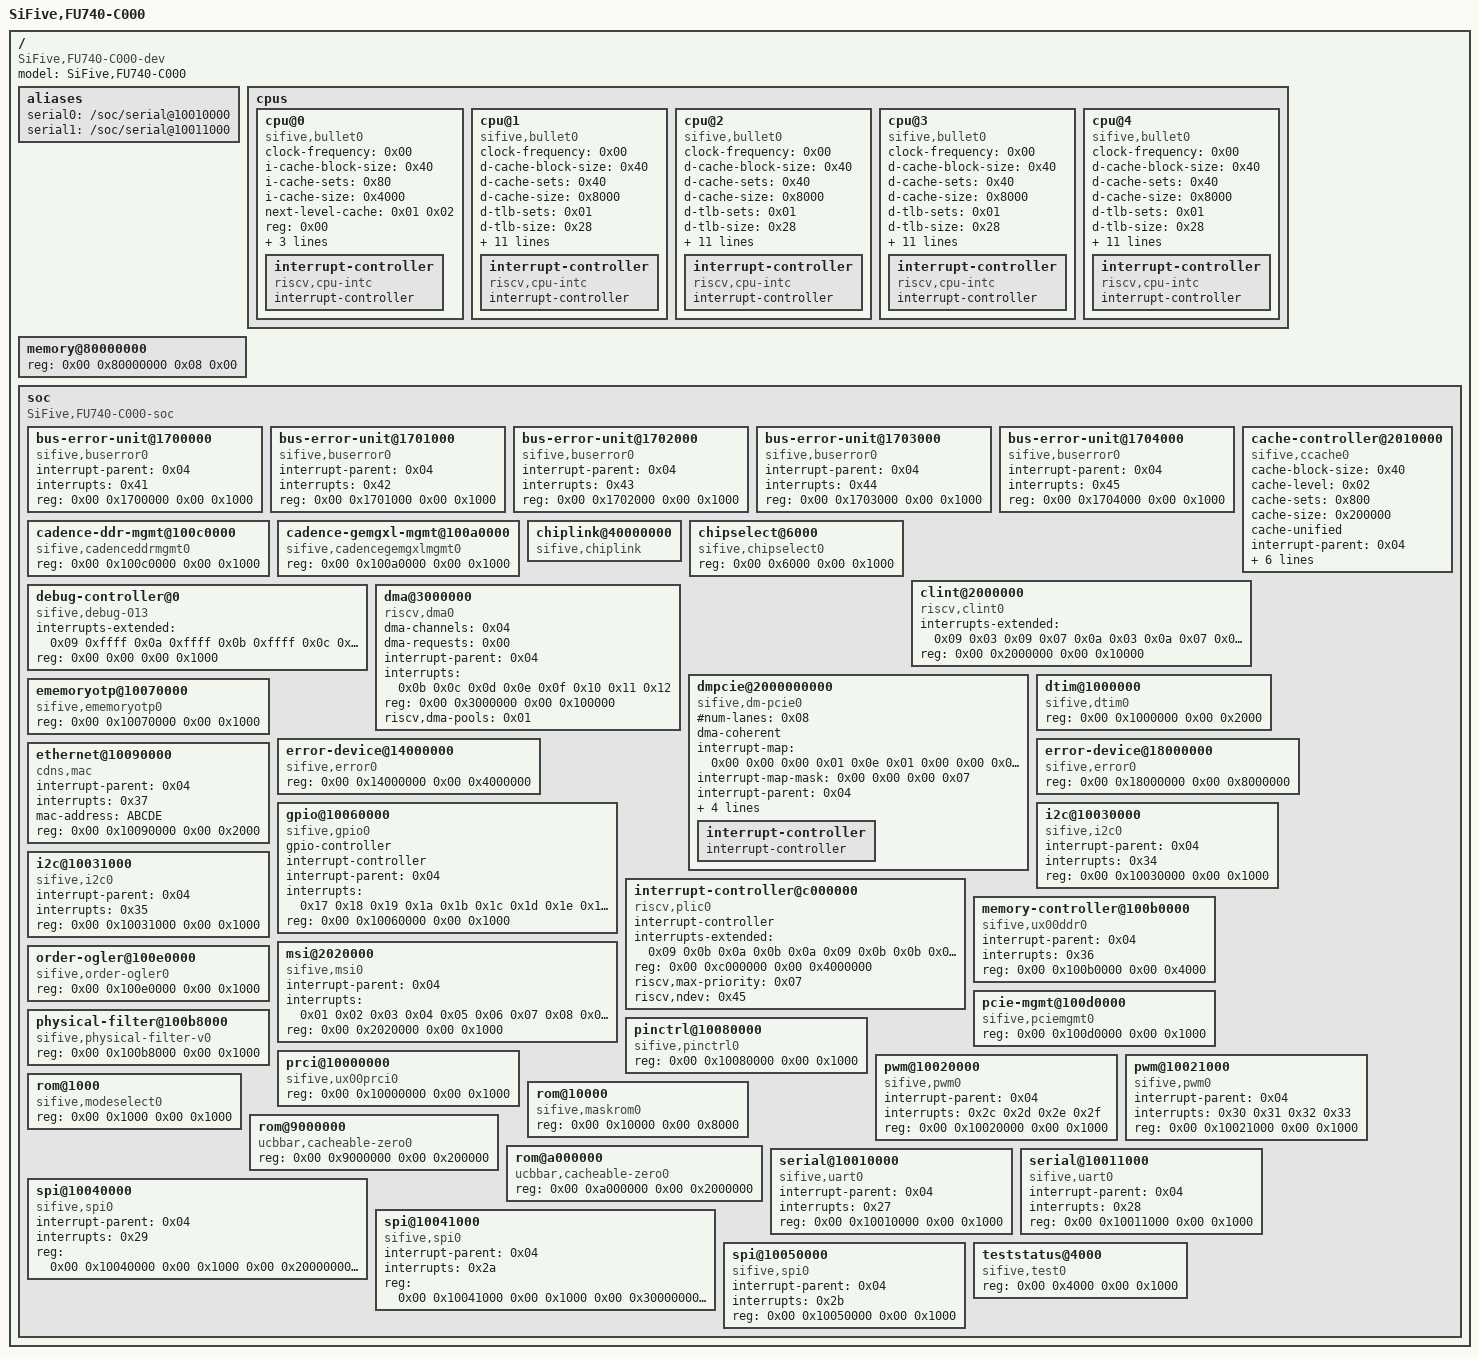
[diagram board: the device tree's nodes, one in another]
/dts-v1/;

/ {
	#address-cells = <0x02>;
	#size-cells = <0x02>;
	compatible = "SiFive,FU740-C000-dev\0fu700-dev\0sifive-dev";
	model = "SiFive,FU740-C000";

	aliases {
		serial0 = "/soc/serial@10010000";
		serial1 = "/soc/serial@10011000";
	};

	cpus {
		#address-cells = <0x01>;
		#size-cells = <0x00>;

		cpu@0 {
			clock-frequency = <0x00>;
			compatible = "sifive,bullet0\0riscv";
			device_type = "cpu";
			i-cache-block-size = <0x40>;
			i-cache-sets = <0x80>;
			i-cache-size = <0x4000>;
			next-level-cache = <0x01 0x02>;
			reg = <0x00>;
			riscv,isa = "rv64imac";
			sifive,dtim = <0x03>;
			status = "okay";
			timebase-frequency = <0xf4240>;

			interrupt-controller {
				#interrupt-cells = <0x01>;
				compatible = "riscv,cpu-intc";
				interrupt-controller;
				linux,phandle = <0x09>;
				phandle = <0x09>;
			};
		};

		cpu@1 {
			clock-frequency = <0x00>;
			compatible = "sifive,bullet0\0riscv";
			d-cache-block-size = <0x40>;
			d-cache-sets = <0x40>;
			d-cache-size = <0x8000>;
			d-tlb-sets = <0x01>;
			d-tlb-size = <0x28>;
			device_type = "cpu";
			i-cache-block-size = <0x40>;
			i-cache-sets = <0x80>;
			i-cache-size = <0x8000>;
			i-tlb-sets = <0x01>;
			i-tlb-size = <0x28>;
			mmu-type = "riscv,sv39";
			next-level-cache = <0x01 0x02>;
			reg = <0x01>;
			riscv,isa = "rv64imafdc";
			status = "okay";
			timebase-frequency = <0xf4240>;
			tlb-split;

			interrupt-controller {
				#interrupt-cells = <0x01>;
				compatible = "riscv,cpu-intc";
				interrupt-controller;
				linux,phandle = <0x0a>;
				phandle = <0x0a>;
			};
		};

		cpu@2 {
			clock-frequency = <0x00>;
			compatible = "sifive,bullet0\0riscv";
			d-cache-block-size = <0x40>;
			d-cache-sets = <0x40>;
			d-cache-size = <0x8000>;
			d-tlb-sets = <0x01>;
			d-tlb-size = <0x28>;
			device_type = "cpu";
			i-cache-block-size = <0x40>;
			i-cache-sets = <0x80>;
			i-cache-size = <0x8000>;
			i-tlb-sets = <0x01>;
			i-tlb-size = <0x28>;
			mmu-type = "riscv,sv39";
			next-level-cache = <0x01 0x02>;
			reg = <0x02>;
			riscv,isa = "rv64imafdc";
			status = "okay";
			timebase-frequency = <0xf4240>;
			tlb-split;

			interrupt-controller {
				#interrupt-cells = <0x01>;
				compatible = "riscv,cpu-intc";
				interrupt-controller;
				linux,phandle = <0x0b>;
				phandle = <0x0b>;
			};
		};

		cpu@3 {
			clock-frequency = <0x00>;
			compatible = "sifive,bullet0\0riscv";
			d-cache-block-size = <0x40>;
			d-cache-sets = <0x40>;
			d-cache-size = <0x8000>;
			d-tlb-sets = <0x01>;
			d-tlb-size = <0x28>;
			device_type = "cpu";
			i-cache-block-size = <0x40>;
			i-cache-sets = <0x80>;
			i-cache-size = <0x8000>;
			i-tlb-sets = <0x01>;
			i-tlb-size = <0x28>;
			mmu-type = "riscv,sv39";
			next-level-cache = <0x01 0x02>;
			reg = <0x03>;
			riscv,isa = "rv64imafdc";
			status = "okay";
			timebase-frequency = <0xf4240>;
			tlb-split;

			interrupt-controller {
				#interrupt-cells = <0x01>;
				compatible = "riscv,cpu-intc";
				interrupt-controller;
				linux,phandle = <0x0c>;
				phandle = <0x0c>;
			};
		};

		cpu@4 {
			clock-frequency = <0x00>;
			compatible = "sifive,bullet0\0riscv";
			d-cache-block-size = <0x40>;
			d-cache-sets = <0x40>;
			d-cache-size = <0x8000>;
			d-tlb-sets = <0x01>;
			d-tlb-size = <0x28>;
			device_type = "cpu";
			i-cache-block-size = <0x40>;
			i-cache-sets = <0x80>;
			i-cache-size = <0x8000>;
			i-tlb-sets = <0x01>;
			i-tlb-size = <0x28>;
			mmu-type = "riscv,sv39";
			next-level-cache = <0x01 0x02>;
			reg = <0x04>;
			riscv,isa = "rv64imafdc";
			status = "okay";
			timebase-frequency = <0xf4240>;
			tlb-split;

			interrupt-controller {
				#interrupt-cells = <0x01>;
				compatible = "riscv,cpu-intc";
				interrupt-controller;
				linux,phandle = <0x0d>;
				phandle = <0x0d>;
			};
		};
	};

	memory@80000000 {
		device_type = "memory";
		reg = <0x00 0x80000000 0x08 0x00>;
		linux,phandle = <0x08>;
		phandle = <0x08>;
	};

	soc {
		#address-cells = <0x02>;
		#size-cells = <0x02>;
		compatible = "SiFive,FU740-C000-soc\0fu700-soc\0sifive-soc\0simple-bus";
		ranges;

		bus-error-unit@1700000 {
			compatible = "sifive,buserror0";
			interrupt-parent = <0x04>;
			interrupts = <0x41>;
			reg = <0x00 0x1700000 0x00 0x1000>;
			reg-names = "control";
		};

		bus-error-unit@1701000 {
			compatible = "sifive,buserror0";
			interrupt-parent = <0x04>;
			interrupts = <0x42>;
			reg = <0x00 0x1701000 0x00 0x1000>;
			reg-names = "control";
		};

		bus-error-unit@1702000 {
			compatible = "sifive,buserror0";
			interrupt-parent = <0x04>;
			interrupts = <0x43>;
			reg = <0x00 0x1702000 0x00 0x1000>;
			reg-names = "control";
		};

		bus-error-unit@1703000 {
			compatible = "sifive,buserror0";
			interrupt-parent = <0x04>;
			interrupts = <0x44>;
			reg = <0x00 0x1703000 0x00 0x1000>;
			reg-names = "control";
		};

		bus-error-unit@1704000 {
			compatible = "sifive,buserror0";
			interrupt-parent = <0x04>;
			interrupts = <0x45>;
			reg = <0x00 0x1704000 0x00 0x1000>;
			reg-names = "control";
		};

		cache-controller@2010000 {
			cache-block-size = <0x40>;
			cache-level = <0x02>;
			cache-sets = <0x800>;
			cache-size = <0x200000>;
			cache-unified;
			compatible = "sifive,ccache0\0cache";
			interrupt-parent = <0x04>;
			interrupts = <0x13 0x14 0x15 0x16>;
			next-level-cache = <0x05 0x06 0x07 0x08>;
			reg = <0x00 0x2010000 0x00 0x1000 0x00 0x8000000 0x00 0x200000>;
			reg-names = "control\0sideband";
			sifive,ecc-granularity = <0x08>;
			sifive,mshr-count = <0x0a>;
			linux,phandle = <0x02>;
			phandle = <0x02>;
		};

		cadence-ddr-mgmt@100c0000 {
			compatible = "sifive,cadenceddrmgmt0";
			reg = <0x00 0x100c0000 0x00 0x1000>;
			reg-names = "control";
		};

		cadence-gemgxl-mgmt@100a0000 {
			compatible = "sifive,cadencegemgxlmgmt0";
			reg = <0x00 0x100a0000 0x00 0x1000>;
			reg-names = "control";
		};

		chiplink@40000000 {
			#address-cells = <0x02>;
			#size-cells = <0x02>;
			compatible = "sifive,chiplink\0simple-bus";
			ranges = <0x18 0x00 0x18 0x00 0x08 0x00 0x00 0x40000000 0x00 0x40000000 0x00 0x20000000 0x10 0x00 0x10 0x00 0x08 0x00>;
			linux,phandle = <0x05>;
			phandle = <0x05>;
		};

		chipselect@6000 {
			compatible = "sifive,chipselect0";
			reg = <0x00 0x6000 0x00 0x1000>;
			reg-names = "control";
		};

		clint@2000000 {
			compatible = "riscv,clint0";
			interrupts-extended = <0x09 0x03 0x09 0x07 0x0a 0x03 0x0a 0x07 0x0b 0x03 0x0b 0x07 0x0c 0x03 0x0c 0x07 0x0d 0x03 0x0d 0x07>;
			reg = <0x00 0x2000000 0x00 0x10000>;
			reg-names = "control";
		};

		debug-controller@0 {
			compatible = "sifive,debug-013\0riscv,debug-013";
			interrupts-extended = <0x09 0xffff 0x0a 0xffff 0x0b 0xffff 0x0c 0xffff 0x0d 0xffff>;
			reg = <0x00 0x00 0x00 0x1000>;
			reg-names = "control";
		};

		dma@3000000 {
			#dma-cells = <0x01>;
			compatible = "riscv,dma0";
			dma-channels = <0x04>;
			dma-requests = <0x00>;
			interrupt-parent = <0x04>;
			interrupts = <0x0b 0x0c 0x0d 0x0e 0x0f 0x10 0x11 0x12>;
			reg = <0x00 0x3000000 0x00 0x100000>;
			reg-names = "control";
			riscv,dma-pools = <0x01>;
		};

		dmpcie@2000000000 {
			#address-cells = <0x03>;
			#interrupt-cells = <0x01>;
			#num-lanes = <0x08>;
			#size-cells = <0x02>;
			compatible = "sifive,dm-pcie0\0snps,dw-pcie";
			device_type = "pci";
			dma-coherent;
			interrupt-map = <0x00 0x00 0x00 0x01 0x0e 0x01 0x00 0x00 0x00 0x02 0x0e 0x02 0x00 0x00 0x00 0x03 0x0e 0x03 0x00 0x00 0x00 0x04 0x0e 0x04>;
			interrupt-map-mask = <0x00 0x00 0x00 0x07>;
			interrupt-names = "msi\0inta\0intb\0intc\0intd";
			interrupt-parent = <0x04>;
			interrupts = <0x38 0x39 0x3a 0x3b 0x3c 0x3d 0x3e 0x3f 0x40>;
			reg = <0x20 0x00 0x20 0x00 0x0e 0x00 0x01 0x00 0x0d 0xf0000000 0x00 0x10000000 0x00 0x60000000 0x00 0x20000000>;
			reg-names = "pcieupper\0dbi\0config\0pcielower";

			interrupt-controller {
				#address-cells = <0x00>;
				#interrupt-cells = <0x01>;
				interrupt-controller;
				linux,phandle = <0x0e>;
				phandle = <0x0e>;
			};
		};

		dtim@1000000 {
			compatible = "sifive,dtim0";
			reg = <0x00 0x1000000 0x00 0x2000>;
			reg-names = "mem";
			linux,phandle = <0x03>;
			phandle = <0x03>;
		};

		ememoryotp@10070000 {
			compatible = "sifive,ememoryotp0";
			reg = <0x00 0x10070000 0x00 0x1000>;
			reg-names = "control";
		};

		error-device@14000000 {
			compatible = "sifive,error0";
			reg = <0x00 0x14000000 0x00 0x4000000>;
			linux,phandle = <0x06>;
			phandle = <0x06>;
		};

		error-device@18000000 {
			compatible = "sifive,error0";
			reg = <0x00 0x18000000 0x00 0x8000000>;
			linux,phandle = <0x01>;
			phandle = <0x01>;
		};

		ethernet@10090000 {
			compatible = "cdns,mac";
			interrupt-parent = <0x04>;
			interrupts = <0x37>;
			mac-address = "ABCDE";
			reg = <0x00 0x10090000 0x00 0x2000>;
			reg-names = "control";
		};

		gpio@10060000 {
			#gpio-cells = <0x02>;
			#interrupt-cells = <0x02>;
			compatible = "sifive,gpio0\0sifive,gpio1";
			gpio-controller;
			interrupt-controller;
			interrupt-parent = <0x04>;
			interrupts = <0x17 0x18 0x19 0x1a 0x1b 0x1c 0x1d 0x1e 0x1f 0x20 0x21 0x22 0x23 0x24 0x25 0x26>;
			reg = <0x00 0x10060000 0x00 0x1000>;
			reg-names = "control";
		};

		i2c@10030000 {
			compatible = "sifive,i2c0";
			interrupt-parent = <0x04>;
			interrupts = <0x34>;
			reg = <0x00 0x10030000 0x00 0x1000>;
			reg-names = "control";
		};

		i2c@10031000 {
			compatible = "sifive,i2c0";
			interrupt-parent = <0x04>;
			interrupts = <0x35>;
			reg = <0x00 0x10031000 0x00 0x1000>;
			reg-names = "control";
		};

		interrupt-controller@c000000 {
			#interrupt-cells = <0x01>;
			compatible = "riscv,plic0";
			interrupt-controller;
			interrupts-extended = <0x09 0x0b 0x0a 0x0b 0x0a 0x09 0x0b 0x0b 0x0b 0x09 0x0c 0x0b 0x0c 0x09 0x0d 0x0b 0x0d 0x09>;
			reg = <0x00 0xc000000 0x00 0x4000000>;
			reg-names = "control";
			riscv,max-priority = <0x07>;
			riscv,ndev = <0x45>;
			linux,phandle = <0x04>;
			phandle = <0x04>;
		};

		memory-controller@100b0000 {
			compatible = "sifive,ux00ddr0";
			interrupt-parent = <0x04>;
			interrupts = <0x36>;
			reg = <0x00 0x100b0000 0x00 0x4000>;
			reg-names = "control";
		};

		msi@2020000 {
			compatible = "sifive,msi0";
			interrupt-parent = <0x04>;
			interrupts = <0x01 0x02 0x03 0x04 0x05 0x06 0x07 0x08 0x09 0x0a>;
			reg = <0x00 0x2020000 0x00 0x1000>;
			reg-names = "control";
		};

		order-ogler@100e0000 {
			compatible = "sifive,order-ogler0";
			reg = <0x00 0x100e0000 0x00 0x1000>;
			reg-names = "control";
		};

		pcie-mgmt@100d0000 {
			compatible = "sifive,pciemgmt0";
			reg = <0x00 0x100d0000 0x00 0x1000>;
			reg-names = "control";
		};

		physical-filter@100b8000 {
			compatible = "sifive,physical-filter-v0";
			reg = <0x00 0x100b8000 0x00 0x1000>;
			reg-names = "control";
		};

		pinctrl@10080000 {
			compatible = "sifive,pinctrl0";
			reg = <0x00 0x10080000 0x00 0x1000>;
			reg-names = "control";
		};

		prci@10000000 {
			compatible = "sifive,ux00prci0";
			reg = <0x00 0x10000000 0x00 0x1000>;
			reg-names = "control";
		};

		pwm@10020000 {
			compatible = "sifive,pwm0";
			interrupt-parent = <0x04>;
			interrupts = <0x2c 0x2d 0x2e 0x2f>;
			reg = <0x00 0x10020000 0x00 0x1000>;
			reg-names = "control";
		};

		pwm@10021000 {
			compatible = "sifive,pwm0";
			interrupt-parent = <0x04>;
			interrupts = <0x30 0x31 0x32 0x33>;
			reg = <0x00 0x10021000 0x00 0x1000>;
			reg-names = "control";
		};

		rom@1000 {
			compatible = "sifive,modeselect0";
			reg = <0x00 0x1000 0x00 0x1000>;
			reg-names = "mem";
		};

		rom@10000 {
			compatible = "sifive,maskrom0";
			reg = <0x00 0x10000 0x00 0x8000>;
			reg-names = "mem";
		};

		rom@9000000 {
			compatible = "ucbbar,cacheable-zero0";
			reg = <0x00 0x9000000 0x00 0x200000>;
		};

		rom@a000000 {
			compatible = "ucbbar,cacheable-zero0";
			reg = <0x00 0xa000000 0x00 0x2000000>;
			linux,phandle = <0x07>;
			phandle = <0x07>;
		};

		serial@10010000 {
			compatible = "sifive,uart0";
			interrupt-parent = <0x04>;
			interrupts = <0x27>;
			reg = <0x00 0x10010000 0x00 0x1000>;
			reg-names = "control";
		};

		serial@10011000 {
			compatible = "sifive,uart0";
			interrupt-parent = <0x04>;
			interrupts = <0x28>;
			reg = <0x00 0x10011000 0x00 0x1000>;
			reg-names = "control";
		};

		spi@10040000 {
			#address-cells = <0x01>;
			#size-cells = <0x00>;
			compatible = "sifive,spi0";
			interrupt-parent = <0x04>;
			interrupts = <0x29>;
			reg = <0x00 0x10040000 0x00 0x1000 0x00 0x20000000 0x00 0x10000000>;
			reg-names = "control\0mem";
		};

		spi@10041000 {
			#address-cells = <0x01>;
			#size-cells = <0x00>;
			compatible = "sifive,spi0";
			interrupt-parent = <0x04>;
			interrupts = <0x2a>;
			reg = <0x00 0x10041000 0x00 0x1000 0x00 0x30000000 0x00 0x10000000>;
			reg-names = "control\0mem";
		};

		spi@10050000 {
			#address-cells = <0x01>;
			#size-cells = <0x00>;
			compatible = "sifive,spi0";
			interrupt-parent = <0x04>;
			interrupts = <0x2b>;
			reg = <0x00 0x10050000 0x00 0x1000>;
			reg-names = "control";
		};

		teststatus@4000 {
			compatible = "sifive,test0";
			reg = <0x00 0x4000 0x00 0x1000>;
			reg-names = "control";
		};
	};
};
